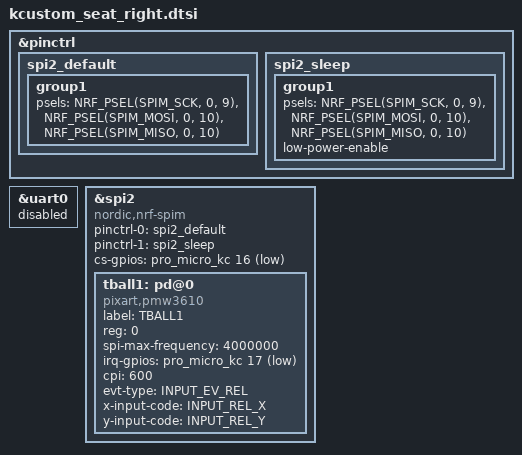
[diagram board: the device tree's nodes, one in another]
/*
 * Copyright (c) 2020 Pete Johanson, Ryan Cross
 *
 * SPDX-License-Identifier: MIT
 */

 #include <zephyr/dt-bindings/input/input-event-codes.h>
 #include <kcustom_seat.dtsi>

&pinctrl {
    spi2_default: spi2_default {
        group1 {
            psels = <NRF_PSEL(SPIM_SCK, 0, 9)>,
                <NRF_PSEL(SPIM_MOSI, 0, 10)>,
                <NRF_PSEL(SPIM_MISO, 0, 10)>;
        };
    };

    spi2_sleep: spi2_sleep {
        group1 {
            psels = <NRF_PSEL(SPIM_SCK, 0, 9)>,
                <NRF_PSEL(SPIM_MOSI, 0, 10)>,
                <NRF_PSEL(SPIM_MISO, 0, 10)>;
            low-power-enable;
        };
    };
};

&uart0 {
	status = "disabled";
};

&spi2 {
	compatible = "nordic,nrf-spim";
	status = "disabled"; // <<< disabled in main .dtsi, okay in .overlay
	tball1: pd@0 {
		compatible = "pixart,pmw3610";
		status = "disabled";
		label = "TBALL1";
		reg = <0>;
		spi-max-frequency = <4000000>;
	};
};

// Config custom gpios
&spi2 {
    status = "okay";
	pinctrl-0 = <&spi2_default>;
	pinctrl-1 = <&spi2_sleep>;
	pinctrl-names = "default", "sleep";
	cs-gpios = <&pro_micro_kc 16 GPIO_ACTIVE_LOW>;
};

&tball1 {
    status = "okay";
    irq-gpios = <&pro_micro_kc 17 (GPIO_ACTIVE_LOW | GPIO_PULL_UP)>;
    cpi = <600>;
    evt-type = <INPUT_EV_REL>;
    x-input-code = <INPUT_REL_X>;
    y-input-code = <INPUT_REL_Y>;
  };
